# nrf52820 register map
Vendor: Nordic Semiconductor; Series: nrf52; File version: 1
CPU: CM4 r0p1, little endian, MPU, no FPU, 3 interrupt priority bits
Registers are 32-bit, read-write, reset 0x0 unless marked. A register's access mark holds for its fields unless they carry their own. Offsets are from the block's base; [hi:lo] are bit positions; {n}, {i} and the like mark numbered series; 'fields as' and 'values as' point back to an identical list.

## GPIOTE — GPIO Tasks and Events
Base 0x40006000
{0x0+4i} TASKS_OUT[{i}] (i=0..7) wo — Description collection: Task for writing to pin specified in CONFIG[n].PSEL. Action on pin is configured in CONFIG[n].POLARITY.
  [0] TASKS_OUT — Task for writing to pin specified in CONFIG[n].PSEL. Action on pin is configured in CONFIG[n].POLARITY.
    1=Trigger task
{0x30+4i} TASKS_SET[{i}] (i=0..7) wo — Description collection: Task for writing to pin specified in CONFIG[n].PSEL. Action on pin is to set it high.
  [0] TASKS_SET — Task for writing to pin specified in CONFIG[n].PSEL. Action on pin is to set it high.
    1=Trigger task
{0x60+4i} TASKS_CLR[{i}] (i=0..7) wo — Description collection: Task for writing to pin specified in CONFIG[n].PSEL. Action on pin is to set it low.
  [0] TASKS_CLR — Task for writing to pin specified in CONFIG[n].PSEL. Action on pin is to set it low.
    1=Trigger task
{0x100+4i} EVENTS_IN[{i}] (i=0..7) — Description collection: Event generated from pin specified in CONFIG[n].PSEL
  [0] EVENTS_IN — Event generated from pin specified in CONFIG[n].PSEL
    0=NotGenerated (Event not generated); 1=Generated (Event generated)
0x17C EVENTS_PORT — Event generated from multiple input GPIO pins with SENSE mechanism enabled
  [0] EVENTS_PORT
    values as EVENTS_IN[0].EVENTS_IN
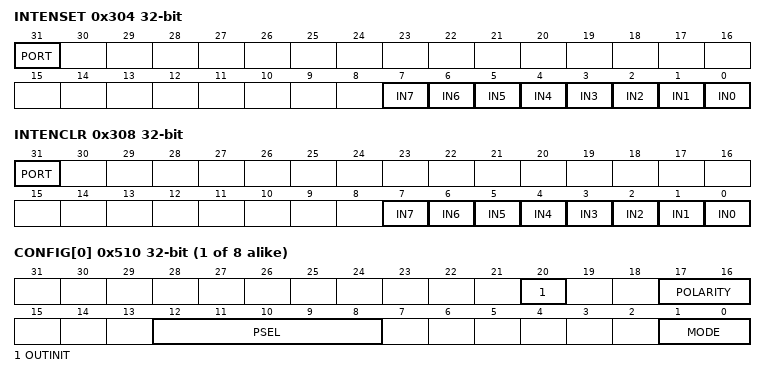
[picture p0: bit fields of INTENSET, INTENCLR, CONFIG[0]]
0x304 INTENSET — Enable interrupt
  [all] fields
    on read: 0=Disabled (Read: Disabled); 1=Enabled (Read: Enabled) | on write: 1=Set (Enable)
  [31] PORT — Write '1' to enable interrupt for event PORT
  [n] IN{n} (n=0..7) — Write '1' to enable interrupt for event IN[{n}]
0x308 INTENCLR — Disable interrupt
  [all] fields
    on read: 0=Disabled (Read: Disabled); 1=Enabled (Read: Enabled) | on write: 1=Clear (Disable)
  [31] PORT — Write '1' to disable interrupt for event PORT
  [n] IN{n} (n=0..7) — Write '1' to disable interrupt for event IN[{n}]
{0x510+4i} CONFIG[{i}] (i=0..7) — Description collection: Configuration for OUT[n], SET[n], and CLR[n] tasks and IN[n] event
  [20] OUTINIT — When in task mode: Initial value of the output when the GPIOTE channel is configured. When in event mode: No effect.
    0=Low (Task mode: Initial value of pin before task triggering is low); 1=High (Task mode: Initial value of pin before task triggering is high)
  [17:16] POLARITY — When In task mode: Operation to be performed on output when OUT[n] task is triggered. When In event mode: Operation on input that shall trigger IN[n] event.
    0=None (Task mode: No effect on pin from OUT[n] task. Event mode: no IN[n] event generated on pin activity.); 1=LoToHi (Task mode: Set pin from OUT[n] task. Event mode: Generate IN[n] event when rising edge on pin.); 2=HiToLo (Task mode: Clear pin from OUT[n] task. Event mode: Generate IN[n] event when falling edge on pin.); 3=Toggle (Task mode: Toggle pin from OUT[n]. Event mode: Generate IN[n] when any change on pin.)
  [12:8] PSEL — GPIO number associated with SET[n], CLR[n], and OUT[n] tasks and IN[n] event
  [1:0] MODE
    0=Disabled. Pin specified by PSEL will not be acquired by the GPIOTE module.; 1=Event mode; 3=Task mode

## TIMER0 — Timer/Counter 0
Base 0x40008000
Same registers: TIMER1 0x40009000, TIMER2 0x4000A000, TIMER3 0x4001A000
0x00 TASKS_START wo — Start Timer
  [0] TASKS_START
    1=Trigger task
0x04 TASKS_STOP wo — Stop Timer
  [0] TASKS_STOP
    1=Trigger task
0x08 TASKS_COUNT wo — Increment Timer (Counter mode only)
  [0] TASKS_COUNT
    1=Trigger task
0x0C TASKS_CLEAR wo — Clear time
  [0] TASKS_CLEAR
    1=Trigger task
0x10 TASKS_SHUTDOWN wo — Deprecated register - Shut down timer
  [0] TASKS_SHUTDOWN — Deprecated field - Shut down timer
    1=Trigger task
{0x40+4i} TASKS_CAPTURE[{i}] (i=0..5) wo — Description collection: Capture Timer value to CC[n] register
  [0] TASKS_CAPTURE — Capture Timer value to CC[n] register
    1=Trigger task
{0x140+4i} EVENTS_COMPARE[{i}] (i=0..5) — Description collection: Compare event on CC[n] match
  [0] EVENTS_COMPARE — Compare event on CC[n] match
    0=NotGenerated (Event not generated); 1=Generated (Event generated)
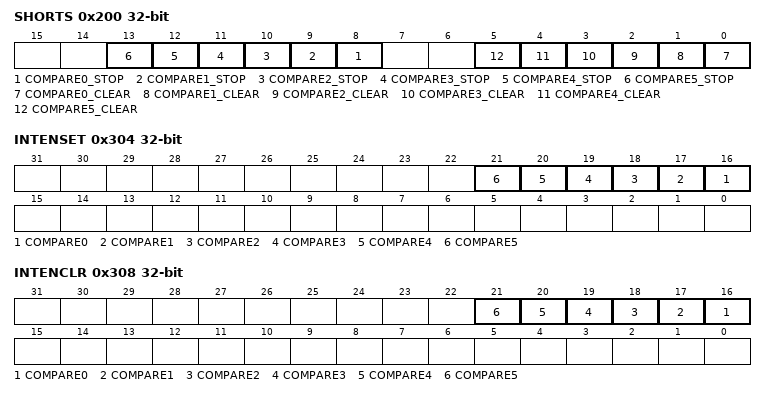
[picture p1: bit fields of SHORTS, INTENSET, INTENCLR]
0x200 SHORTS — Shortcuts between local events and tasks
  [all] fields
    0=Disabled (Disable shortcut); 1=Enabled (Enable shortcut)
  [n+8] COMPARE{n}_STOP (n=0..5) — Shortcut between event COMPARE[{n}] and task STOP
  [n] COMPARE{n}_CLEAR (n=0..5) — Shortcut between event COMPARE[{n}] and task CLEAR
0x304 INTENSET — Enable interrupt
  [all] fields
    on read: 0=Disabled (Read: Disabled); 1=Enabled (Read: Enabled) | on write: 1=Set (Enable)
  [n+16] COMPARE{n} (n=0..5) — Write '1' to enable interrupt for event COMPARE[{n}]
0x308 INTENCLR — Disable interrupt
  [all] fields
    on read: 0=Disabled (Read: Disabled); 1=Enabled (Read: Enabled) | on write: 1=Clear (Disable)
  [n+16] COMPARE{n} (n=0..5) — Write '1' to disable interrupt for event COMPARE[{n}]
0x504 MODE — Timer mode selection
  [1:0] MODE — Timer mode
    0=Timer (Select Timer mode); 1=Counter (Deprecated enumerator - Select Counter mode); 2=LowPowerCounter (Select Low Power Counter mode)
0x508 BITMODE — Configure the number of bits used by the TIMER
  [1:0] BITMODE — Timer bit width
    0=16 bit timer bit width; 1=08Bit (8 bit timer bit width); 2=24 bit timer bit width; 3=32 bit timer bit width
0x510 PRESCALER reset 0x4 — Timer prescaler register
  [3:0] PRESCALER — Prescaler value
{0x540+4i} CC[{i}] (i=0..5) — Description collection: Capture/Compare register n
  [31:0] CC — Capture/Compare value

## Notices in the file
Copyright (c) 2010 - 2023, Nordic Semiconductor ASA
All rights reserved.
Redistribution and use in source and binary forms, with or without modification,
are permitted provided that the following conditions are met:
1. Redistributions of source code must retain the above copyright notice, this
list of conditions and the following disclaimer.
2. Redistributions in binary form, except as embedded into a Nordic
Semiconductor ASA integrated circuit in a product or a software update for
such product, must reproduce the above copyright notice, this list of
conditions and the following disclaimer in the documentation and/or other
materials provided with the distribution.
3. Neither the name of Nordic Semiconductor ASA nor the names of its
contributors may be used to endorse or promote products derived from this
software without specific prior written permission.
4. This software, with or without modification, must only be used with a
Nordic Semiconductor ASA integrated circuit.
5. Any software provided in binary form under this license must not be reverse
engineered, decompiled, modified and/or disassembled.
THIS SOFTWARE IS PROVIDED BY NORDIC SEMICONDUCTOR ASA "AS IS" AND ANY EXPRESS
OR IMPLIED WARRANTIES, INCLUDING, BUT NOT LIMITED TO, THE IMPLIED WARRANTIES
OF MERCHANTABILITY, NONINFRINGEMENT, AND FITNESS FOR A PARTICULAR PURPOSE ARE
DISCLAIMED. IN NO EVENT SHALL NORDIC SEMICONDUCTOR ASA OR CONTRIBUTORS BE
LIABLE FOR ANY DIRECT, INDIRECT, INCIDENTAL, SPECIAL, EXEMPLARY, OR
CONSEQUENTIAL DAMAGES (INCLUDING, BUT NOT LIMITED TO, PROCUREMENT OF SUBSTITUTE
GOODS OR SERVICES; LOSS OF USE, DATA, OR PROFITS; OR BUSINESS INTERRUPTION)
HOWEVER CAUSED AND ON ANY THEORY OF LIABILITY, WHETHER IN CONTRACT, STRICT
LIABILITY, OR TORT (INCLUDING NEGLIGENCE OR OTHERWISE) ARISING IN ANY WAY OUT
OF THE USE OF THIS SOFTWARE, EVEN IF ADVISED OF THE POSSIBILITY OF SUCH DAMAGE.
